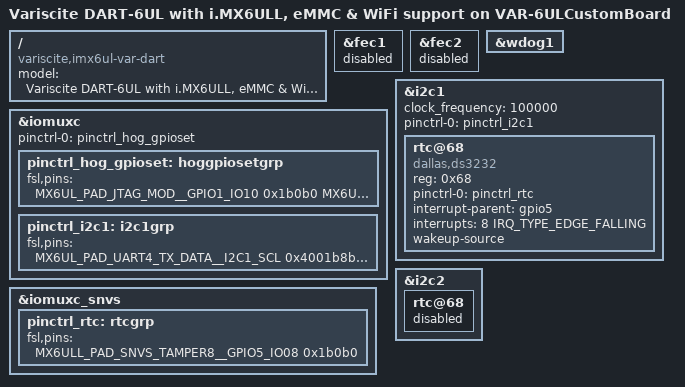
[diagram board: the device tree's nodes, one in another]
/*
 * Copyright (C) 2016-2019 Variscite Ltd. - https://www.variscite.com
 *
 * This program is free software; you can redistribute it and/or modify
 * it under the terms of the GNU General Public License version 2 as
 * published by the Free Software Foundation.
 */

/dts-v1/;

#include "imx6ull.dtsi"

#include "imx6ull-var-dart.dtsi"
#include "imx6ul-imx6ull-var-dart-emmc.dtsi"
#include "imx6ul-imx6ull-var-dart-wifi.dtsi"

#include "imx6ull-var-dart-6ulcustomboard.dtsi"

/ {
	model = "Variscite DART-6UL with i.MX6ULL, eMMC & WiFi support on VAR-6ULCustomBoard";
	compatible = "variscite,imx6ul-var-dart", "fsl,imx6ull";
};


&fec1 {
	status = "disabled";
};

&fec2 {
	status = "disabled";
};

&wdog1 {
	/delete-property/ pinctrl-names;
	/delete-property/ pinctrl-0;
	/delete-property/ fsl,ext-reset-output;
};

&iomuxc {
	pinctrl-names = "default";
	pinctrl-0 = <&pinctrl_hog_gpioset>;

	pinctrl_hog_gpioset: hoggpiosetgrp {
		fsl,pins = <
			MX6UL_PAD_JTAG_MOD__GPIO1_IO10		0x1b0b0
			MX6UL_PAD_GPIO1_IO08__GPIO1_IO08	0x1b0b0
		>;
	};

	pinctrl_i2c1: i2c1grp {
		fsl,pins = <
			MX6UL_PAD_UART4_TX_DATA__I2C1_SCL	0x4001b8b0
			MX6UL_PAD_UART4_RX_DATA__I2C1_SDA	0x4001b8b0
		>;
	};
};

&iomuxc_snvs {

	pinctrl_rtc: rtcgrp {
		fsl,pins = <
			MX6ULL_PAD_SNVS_TAMPER8__GPIO5_IO08		0x1b0b0 /* RTC alarm IRQ. PullUp 47k */
		>;
	};
};

&i2c1 {
	clock_frequency = <100000>;
	pinctrl-names = "default";
	pinctrl-0 = <&pinctrl_i2c1>;
	status = "okay";
	rtc@68 {
		compatible = "dallas,ds3232";
		reg = <0x68>;
		pinctrl-names = "default";
		pinctrl-0 = <&pinctrl_rtc>;
		interrupt-parent = <&gpio5>;
		interrupts = <8 IRQ_TYPE_EDGE_FALLING>;
		wakeup-source;
	};
};

&i2c2 {
	rtc@68 {
		status = "disabled";
	};
};

